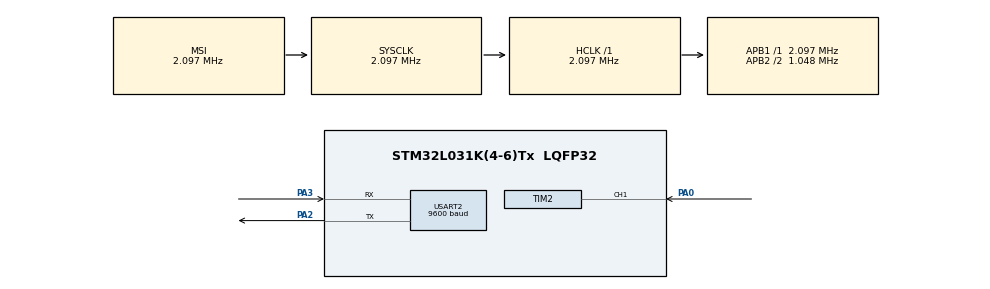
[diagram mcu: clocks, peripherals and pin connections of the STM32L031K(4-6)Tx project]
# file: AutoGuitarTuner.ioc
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Mcu.Family=STM32L0
Mcu.Name=STM32L031K(4-6)Tx
Mcu.Package=LQFP32
NVIC.TIM2_IRQn=true\:0\:0\:false\:false\:true\:true\:true\:true
PA0-CK_IN.Signal=S_TIM2_CH1
PA2.Mode=Asynchronous
PA2.Signal=USART2_TX
PA3.Mode=Asynchronous
PA3.Signal=USART2_RX
ProjectManager.HeapSize=0x200
ProjectManager.StackSize=0x400
ProjectManager.TargetToolchain=STM32CubeIDE
RCC.AHBFreq_Value=2097000
RCC.APB1Freq_Value=2097000
RCC.APB1TimFreq_Value=2097000
RCC.APB2CLKDivider=RCC_HCLK_DIV2
RCC.APB2Freq_Value=1048500
RCC.APB2TimCLKDivider=2
RCC.APB2TimFreq_Value=2097000
RCC.HCLKFreq_Value=2097000
RCC.HSE_VALUE=8000000
RCC.HSI16_VALUE=16000000
RCC.HSI_VALUE=16000000
RCC.LSE_VALUE=32768
RCC.MSI_VALUE=2097000
RCC.SYSCLKFreq_VALUE=2097000
RCC.VCOOutputFreq_Value=48000000
SH.S_TIM2_CH1.0=TIM2_CH1,Input_Capture1_from_TI1
TIM2.Channel-Input_Capture1_from_TI1=TIM_CHANNEL_1
TIM2.Prescaler=2-1
USART2.BaudRate=9600
USART2.Mode=MODE_TX_RX
USART2.Parity=PARITY_NONE
USART2.VirtualMode-Asynchronous=VM_ASYNC
USART2.WordLength=WORDLENGTH_8B
VP_TIM2_VS_ClockSourceINT.Mode=Internal
board=custom

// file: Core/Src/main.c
/* USER CODE BEGIN Header */
/**
  ******************************************************************************
  * @file           : main.c
  * @brief          : Main program body
  ******************************************************************************
  * @attention
  *
  * Copyright (c) 2022 STMicroelectronics.
  * All rights reserved.
  *
  * This software is licensed under terms that can be found in the LICENSE file
  * in the root directory of this software component.
  * If no LICENSE file comes with this software, it is provided AS-IS.
  *
  ******************************************************************************
  */
/* USER CODE END Header */
#include "main.h"

/* USER CODE BEGIN Includes */
#include <string.h>
#include <stdio.h>
/* USER CODE END Includes */

/* USER CODE BEGIN PD */
#define TIMCLOCK 2097000
#define PRESCALAR 2
/* USER CODE END PD */

TIM_HandleTypeDef htim2;

UART_HandleTypeDef huart2;

/* USER CODE BEGIN PV */
float measuredFrequency = 0;
/* USER CODE END PV */

void SystemClock_Config(void);
static void MX_GPIO_Init(void);
static void MX_TIM2_Init(void);
static void MX_USART2_UART_Init(void);

/* USER CODE BEGIN 0 */

char getCurrentNote(float frequency) {
  //Takes calculated frequency as parameter and determines note based on its range
	if(frequency > 50 && frequency <= 91) {
		return 'E';
	}
	else if(frequency > 91 && frequency <= 125) {
		return 'A';
	}
	else if(frequency > 125 && frequency <= 180) {
		return 'D';
	}
	else if(frequency > 180 && frequency <= 220) {
		return 'G';
	}
	else if(frequency > 220 && frequency <= 280) {
		return 'B';
	}
	else if(frequency > 280 && frequency <= 400) {
		return 'E';
	}
	else {
		return 'N';
	}
}

/* USER CODE END 0 */

int main(void)
{

  /* MCU Configuration--------------------------------------------------------*/

  /* Reset of all peripherals, Initializes the Flash interface and the Systick. */
  HAL_Init();

  /* Configure the system clock */
  SystemClock_Config();

  /* Initialize all configured peripherals */
  MX_GPIO_Init();
  MX_TIM2_Init();
  MX_USART2_UART_Init();
  /* USER CODE BEGIN 2 */

  HAL_TIM_IC_Start_IT(&htim2, TIM_CHANNEL_1);

  /* USER CODE END 2 */

  /* Infinite loop */
  while (1)
  {

  }
}

void SystemClock_Config(void)
{
  RCC_OscInitTypeDef RCC_OscInitStruct = {0};
  RCC_ClkInitTypeDef RCC_ClkInitStruct = {0};
  RCC_PeriphCLKInitTypeDef PeriphClkInit = {0};

  /** Configure the main internal regulator output voltage
  */
  __HAL_PWR_VOLTAGESCALING_CONFIG(PWR_REGULATOR_VOLTAGE_SCALE1);

  /** Initializes the RCC Oscillators according to the specified parameters
  * in the RCC_OscInitTypeDef structure.
  */
  RCC_OscInitStruct.OscillatorType = RCC_OSCILLATORTYPE_MSI;
  RCC_OscInitStruct.MSIState = RCC_MSI_ON;
  RCC_OscInitStruct.MSICalibrationValue = 0;
  RCC_OscInitStruct.MSIClockRange = RCC_MSIRANGE_5;
  RCC_OscInitStruct.PLL.PLLState = RCC_PLL_NONE;
  if (HAL_RCC_OscConfig(&RCC_OscInitStruct) != HAL_OK)
  {
    Error_Handler();
  }

  /** Initializes the CPU, AHB and APB buses clocks
  */
  RCC_ClkInitStruct.ClockType = RCC_CLOCKTYPE_HCLK|RCC_CLOCKTYPE_SYSCLK
                              |RCC_CLOCKTYPE_PCLK1|RCC_CLOCKTYPE_PCLK2;
  RCC_ClkInitStruct.SYSCLKSource = RCC_SYSCLKSOURCE_MSI;
  RCC_ClkInitStruct.AHBCLKDivider = RCC_SYSCLK_DIV1;
  RCC_ClkInitStruct.APB1CLKDivider = RCC_HCLK_DIV1;
  RCC_ClkInitStruct.APB2CLKDivider = RCC_HCLK_DIV2;

  if (HAL_RCC_ClockConfig(&RCC_ClkInitStruct, FLASH_LATENCY_0) != HAL_OK)
  {
    Error_Handler();
  }
  PeriphClkInit.PeriphClockSelection = RCC_PERIPHCLK_USART2;
  PeriphClkInit.Usart2ClockSelection = RCC_USART2CLKSOURCE_PCLK1;
  if (HAL_RCCEx_PeriphCLKConfig(&PeriphClkInit) != HAL_OK)
  {
    Error_Handler();
  }
}

static void MX_TIM2_Init(void)
{

  TIM_ClockConfigTypeDef sClockSourceConfig = {0};
  TIM_MasterConfigTypeDef sMasterConfig = {0};
  TIM_IC_InitTypeDef sConfigIC = {0};

  htim2.Instance = TIM2;
  htim2.Init.Prescaler = 2-1;
  htim2.Init.CounterMode = TIM_COUNTERMODE_UP;
  htim2.Init.Period = 65535;
  htim2.Init.ClockDivision = TIM_CLOCKDIVISION_DIV1;
  htim2.Init.AutoReloadPreload = TIM_AUTORELOAD_PRELOAD_DISABLE;
  if (HAL_TIM_Base_Init(&htim2) != HAL_OK)
  {
    Error_Handler();
  }
  sClockSourceConfig.ClockSource = TIM_CLOCKSOURCE_INTERNAL;
  if (HAL_TIM_ConfigClockSource(&htim2, &sClockSourceConfig) != HAL_OK)
  {
    Error_Handler();
  }
  if (HAL_TIM_IC_Init(&htim2) != HAL_OK)
  {
    Error_Handler();
  }
  sMasterConfig.MasterOutputTrigger = TIM_TRGO_RESET;
  sMasterConfig.MasterSlaveMode = TIM_MASTERSLAVEMODE_DISABLE;
  if (HAL_TIMEx_MasterConfigSynchronization(&htim2, &sMasterConfig) != HAL_OK)
  {
    Error_Handler();
  }
  sConfigIC.ICPolarity = TIM_INPUTCHANNELPOLARITY_RISING;
  sConfigIC.ICSelection = TIM_ICSELECTION_DIRECTTI;
  sConfigIC.ICPrescaler = TIM_ICPSC_DIV1;
  sConfigIC.ICFilter = 0;
  if (HAL_TIM_IC_ConfigChannel(&htim2, &sConfigIC, TIM_CHANNEL_1) != HAL_OK)
  {
    Error_Handler();
  }

}

static void MX_USART2_UART_Init(void)
{

  huart2.Instance = USART2;
  huart2.Init.BaudRate = 9600;
  huart2.Init.WordLength = UART_WORDLENGTH_8B;
  huart2.Init.StopBits = UART_STOPBITS_1;
  huart2.Init.Parity = UART_PARITY_NONE;
  huart2.Init.Mode = UART_MODE_TX_RX;
  huart2.Init.HwFlowCtl = UART_HWCONTROL_NONE;
  huart2.Init.OverSampling = UART_OVERSAMPLING_16;
  huart2.Init.OneBitSampling = UART_ONE_BIT_SAMPLE_DISABLE;
  huart2.AdvancedInit.AdvFeatureInit = UART_ADVFEATURE_NO_INIT;
  if (HAL_UART_Init(&huart2) != HAL_OK)
  {
    Error_Handler();
  }

}

static void MX_GPIO_Init(void)
{

  /* GPIO Ports Clock Enable */
  __HAL_RCC_GPIOA_CLK_ENABLE();

}

void Error_Handler(void)
{
  __disable_irq();
  while (1)
  {
  }
}
